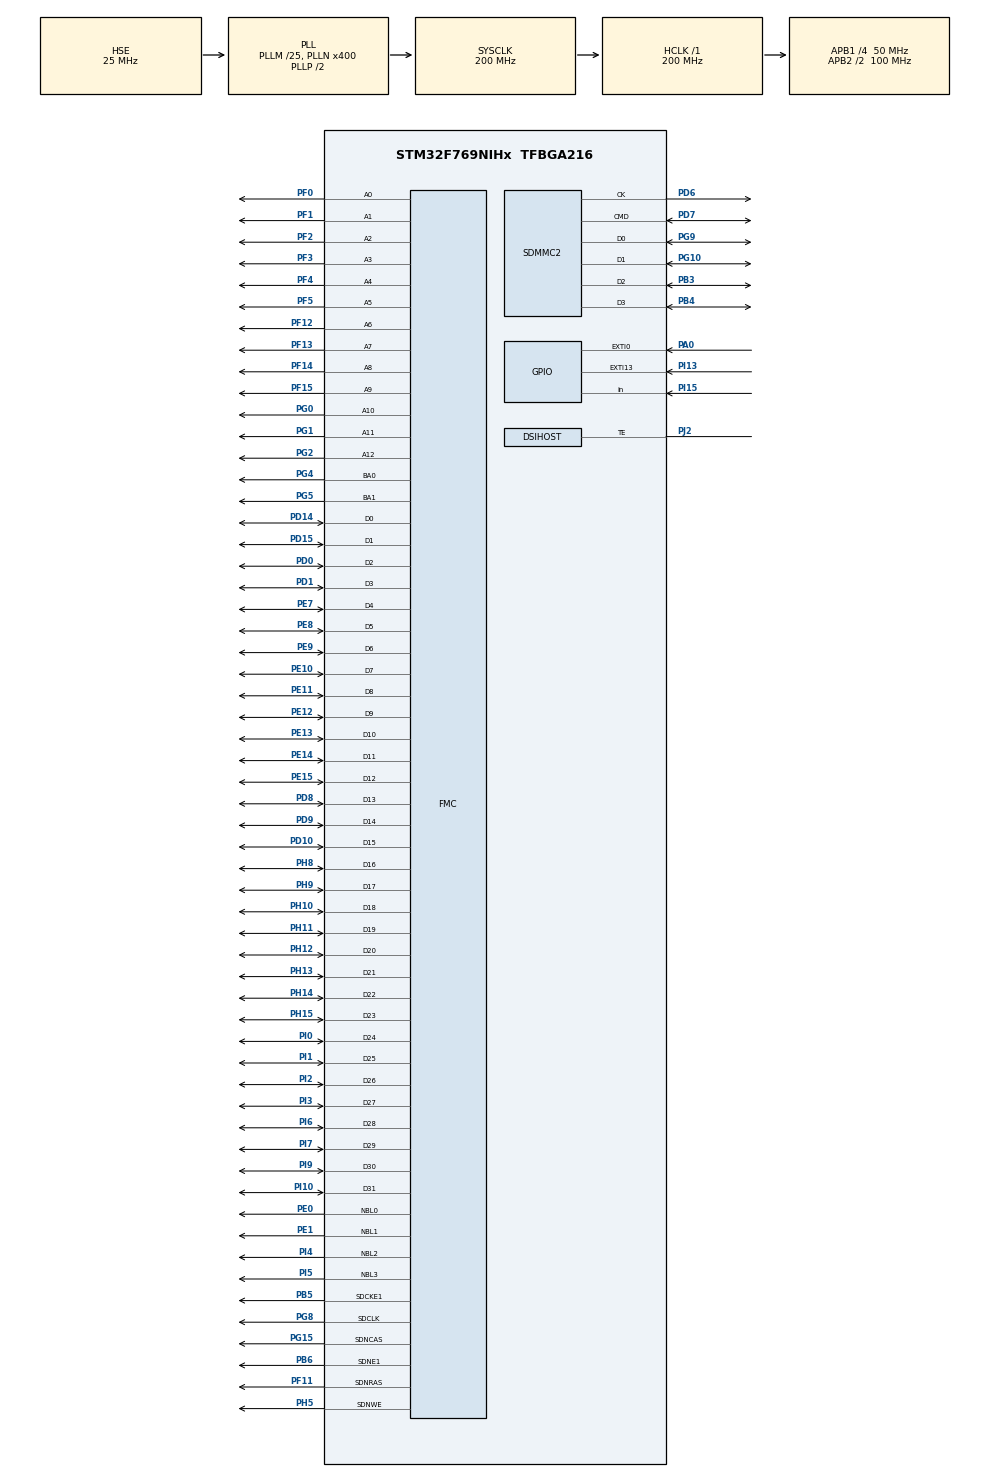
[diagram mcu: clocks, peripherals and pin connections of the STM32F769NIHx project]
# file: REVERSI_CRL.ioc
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ADC1.Channel-0\#ChannelRegularConversion=ADC_CHANNEL_TEMPSENSOR
ADC1.ContinuousConvMode=ENABLE
ADC1.EOCSelection=ADC_EOC_SEQ_CONV
ADC1.NbrOfConversionFlag=1
ADC1.Rank-0\#ChannelRegularConversion=1
ADC1.SamplingTime-0\#ChannelRegularConversion=ADC_SAMPLETIME_56CYCLES
ADC1.master=1
CORTEX_M7.CPU_DCache=Enabled
CORTEX_M7.CPU_ICache=Enabled
DSIHOST_CKN.Mode=DSIHost_Adapted_TE
DSIHOST_CKN.Signal=DSIHOST_CKN
DSIHOST_CKP.Mode=DSIHost_Adapted_TE
DSIHOST_CKP.Signal=DSIHOST_CKP
DSIHOST_D0N.Mode=DSIHost_Adapted_TE
DSIHOST_D0N.Signal=DSIHOST_D0N
DSIHOST_D0P.Mode=DSIHost_Adapted_TE
DSIHOST_D0P.Signal=DSIHOST_D0P
DSIHOST_D1N.Mode=DSIHost_Adapted_TE
DSIHOST_D1N.Signal=DSIHOST_D1N
DSIHOST_D1P.Mode=DSIHost_Adapted_TE
DSIHOST_D1P.Signal=DSIHOST_D1P
FATFS.BSP.number=1
FATFS0.BSP.STBoard=false
FATFS0.BSP.api=Unknown
FATFS0.BSP.i2caddr=0
FATFS0.BSP.instance=PI15
FATFS0.BSP.ip=GPIO
FATFS0.BSP.mode=Input
FATFS0.BSP.name=Detect_SDIO
FATFS0.BSP.solution=PI15
Mcu.Family=STM32F7
Mcu.Name=STM32F769NIHx
Mcu.Package=TFBGA216
NVIC.ADC_IRQn=true\:0\:0\:false\:false\:true\:true\:true
NVIC.EXTI0_IRQn=true\:0\:0\:false\:false\:true\:true\:true
NVIC.EXTI15_10_IRQn=true\:0\:0\:false\:false\:true\:true\:true
NVIC.PriorityGroup=NVIC_PRIORITYGROUP_4
NVIC.TIM6_DAC_IRQn=true\:0\:0\:false\:false\:true\:true\:true
NVIC.TIM7_IRQn=true\:0\:0\:false\:false\:true\:true\:true
PA0/WKUP.Signal=GPXTI0
PB3.Mode=SD_4_bits_Wide_bus
PB3.Signal=SDMMC2_D2
PB4.Mode=SD_4_bits_Wide_bus
PB4.Signal=SDMMC2_D3
PB5.Mode=SdramChipSelect2_1
PB5.Signal=FMC_SDCKE1
PB6.Mode=SdramChipSelect2_1
PB6.Signal=FMC_SDNE1
PD0.Signal=FMC_D2_DA2
PD1.Signal=FMC_D3_DA3
PD10.Signal=FMC_D15_DA15
PD14.Signal=FMC_D0_DA0
PD15.Signal=FMC_D1_DA1
PD6.Mode=SD_4_bits_Wide_bus
PD6.Signal=SDMMC2_CK
PD7.Mode=SD_4_bits_Wide_bus
PD7.Signal=SDMMC2_CMD
PD8.Signal=FMC_D13_DA13
PD9.Signal=FMC_D14_DA14
PE0.Signal=FMC_NBL0
PE1.Signal=FMC_NBL1
PE10.Signal=FMC_D7_DA7
PE11.Signal=FMC_D8_DA8
PE12.Signal=FMC_D9_DA9
PE13.Signal=FMC_D10_DA10
PE14.Signal=FMC_D11_DA11
PE15.Signal=FMC_D12_DA12
PE7.Signal=FMC_D4_DA4
PE8.Signal=FMC_D5_DA5
PE9.Signal=FMC_D6_DA6
PF0.Signal=FMC_A0
PF1.Signal=FMC_A1
PF11.Signal=FMC_SDNRAS
PF12.Signal=FMC_A6
PF13.Signal=FMC_A7
PF14.Signal=FMC_A8
PF15.Signal=FMC_A9
PF2.Signal=FMC_A2
PF3.Signal=FMC_A3
PF4.Signal=FMC_A4
PF5.Signal=FMC_A5
PG0.Signal=FMC_A10
PG1.Signal=FMC_A11
PG10.Mode=SD_4_bits_Wide_bus
PG10.Signal=SDMMC2_D1
PG15.Signal=FMC_SDNCAS
PG2.Signal=FMC_A12
PG4.Signal=FMC_A14_BA0
PG5.Signal=FMC_A15_BA1
PG8.Signal=FMC_SDCLK
PG9.Mode=SD_4_bits_Wide_bus
PG9.Signal=SDMMC2_D0
PH0/OSC_IN.Mode=HSE-External-Oscillator
PH0/OSC_IN.Signal=RCC_OSC_IN
PH1/OSC_OUT.Mode=HSE-External-Oscillator
PH1/OSC_OUT.Signal=RCC_OSC_OUT
PH10.Signal=FMC_D18
PH11.Signal=FMC_D19
PH12.Signal=FMC_D20
PH13.Signal=FMC_D21
PH14.Signal=FMC_D22
PH15.Signal=FMC_D23
PH5.Signal=FMC_SDNWE
PH8.Signal=FMC_D16
PH9.Signal=FMC_D17
PI0.Signal=FMC_D24
PI1.Signal=FMC_D25
PI10.Signal=FMC_D31
PI13.Signal=GPXTI13
PI15.Signal=GPIO_Input
PI2.Signal=FMC_D26
PI3.Signal=FMC_D27
PI4.Signal=FMC_NBL2
PI5.Signal=FMC_NBL3
PI6.Signal=FMC_D28
PI7.Signal=FMC_D29
PI9.Signal=FMC_D30
PJ2.Mode=DSIHost_Adapted_TE
PJ2.Signal=DSIHOST_TE
ProjectManager.HeapSize=0x200
ProjectManager.StackSize=0x400
ProjectManager.TargetToolchain=STM32CubeIDE
RCC.AHBFreq_Value=200000000
RCC.APB1CLKDivider=RCC_HCLK_DIV4
RCC.APB1Freq_Value=50000000
RCC.APB1TimFreq_Value=100000000
RCC.APB2CLKDivider=RCC_HCLK_DIV2
RCC.APB2Freq_Value=100000000
RCC.APB2TimFreq_Value=200000000
RCC.CortexFreq_Value=200000000
RCC.HCLKFreq_Value=200000000
RCC.HSE_VALUE=25000000
RCC.HSI_VALUE=16000000
RCC.LSE_VALUE=32768
RCC.PLLI2SN=96
RCC.PLLM=25
RCC.PLLN=400
RCC.PLLQ=8
RCC.PLLSourceVirtual=RCC_PLLSOURCE_HSE
RCC.SDMMC2ClockSelection=RCC_SDMMC2CLKSOURCE_CLK48
RCC.SYSCLKFreq_VALUE=200000000
RCC.SYSCLKSource=RCC_SYSCLKSOURCE_PLLCLK
RCC.USBFreq_Value=50000000
RCC.VCOOutputFreq_Value=400000000
SH.FMC_A0.0=FMC_A0,13b-sda1
SH.FMC_A1.0=FMC_A1,13b-sda1
SH.FMC_A10.0=FMC_A10,13b-sda1
SH.FMC_A11.0=FMC_A11,13b-sda1
SH.FMC_A12.0=FMC_A12,13b-sda1
SH.FMC_A14_BA0.0=FMC_BA0,FourSdramBanks1
SH.FMC_A15_BA1.0=FMC_BA1,FourSdramBanks1
SH.FMC_A2.0=FMC_A2,13b-sda1
SH.FMC_A3.0=FMC_A3,13b-sda1
SH.FMC_A4.0=FMC_A4,13b-sda1
SH.FMC_A5.0=FMC_A5,13b-sda1
SH.FMC_A6.0=FMC_A6,13b-sda1
SH.FMC_A7.0=FMC_A7,13b-sda1
SH.FMC_A8.0=FMC_A8,13b-sda1
SH.FMC_A9.0=FMC_A9,13b-sda1
SH.FMC_D0_DA0.0=FMC_D0,sd-32b-d1
SH.FMC_D10_DA10.0=FMC_D10,sd-32b-d1
SH.FMC_D11_DA11.0=FMC_D11,sd-32b-d1
SH.FMC_D12_DA12.0=FMC_D12,sd-32b-d1
SH.FMC_D13_DA13.0=FMC_D13,sd-32b-d1
SH.FMC_D14_DA14.0=FMC_D14,sd-32b-d1
SH.FMC_D15_DA15.0=FMC_D15,sd-32b-d1
SH.FMC_D16.0=FMC_D16,sd-32b-d1
SH.FMC_D17.0=FMC_D17,sd-32b-d1
SH.FMC_D18.0=FMC_D18,sd-32b-d1
SH.FMC_D19.0=FMC_D19,sd-32b-d1
SH.FMC_D1_DA1.0=FMC_D1,sd-32b-d1
SH.FMC_D20.0=FMC_D20,sd-32b-d1
SH.FMC_D21.0=FMC_D21,sd-32b-d1
SH.FMC_D22.0=FMC_D22,sd-32b-d1
SH.FMC_D23.0=FMC_D23,sd-32b-d1
SH.FMC_D24.0=FMC_D24,sd-32b-d1
SH.FMC_D25.0=FMC_D25,sd-32b-d1
SH.FMC_D26.0=FMC_D26,sd-32b-d1
SH.FMC_D27.0=FMC_D27,sd-32b-d1
SH.FMC_D28.0=FMC_D28,sd-32b-d1
SH.FMC_D29.0=FMC_D29,sd-32b-d1
SH.FMC_D2_DA2.0=FMC_D2,sd-32b-d1
SH.FMC_D30.0=FMC_D30,sd-32b-d1
SH.FMC_D31.0=FMC_D31,sd-32b-d1
SH.FMC_D3_DA3.0=FMC_D3,sd-32b-d1
SH.FMC_D4_DA4.0=FMC_D4,sd-32b-d1
SH.FMC_D5_DA5.0=FMC_D5,sd-32b-d1
SH.FMC_D6_DA6.0=FMC_D6,sd-32b-d1
SH.FMC_D7_DA7.0=FMC_D7,sd-32b-d1
SH.FMC_D8_DA8.0=FMC_D8,sd-32b-d1
SH.FMC_D9_DA9.0=FMC_D9,sd-32b-d1
SH.FMC_NBL0.0=FMC_NBL0,Sd4ByteEnable1
SH.FMC_NBL1.0=FMC_NBL1,Sd4ByteEnable1
SH.FMC_NBL2.0=FMC_NBL2,Sd4ByteEnable1
SH.FMC_NBL3.0=FMC_NBL3,Sd4ByteEnable1
SH.FMC_SDCLK.0=FMC_SDCLK,13b-sda1
SH.FMC_SDNCAS.0=FMC_SDNCAS,13b-sda1
SH.FMC_SDNRAS.0=FMC_SDNRAS,13b-sda1
SH.FMC_SDNWE.0=FMC_SDNWE,13b-sda1
TIM6.Period=9999
TIM6.Prescaler=9999
TIM7.Period=9999
TIM7.Prescaler=19999
VP_ADC1_TempSens_Input.Mode=IN-TempSens
VP_DMA2D_VS_DMA2D.Mode=DMA2D_Activate
VP_FATFS_VS_SDIO.Mode=SDIO
VP_LTDC_DSIMode.Mode=RGB888
VP_TIM6_VS_ClockSourceINT.Mode=Enable_Timer
VP_TIM7_VS_ClockSourceINT.Mode=Enable_Timer
board=STM32F769I-DISC1

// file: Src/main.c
/* USER CODE BEGIN Header */
/**
 ******************************************************************************
 * @file           : main.c
 * @brief          : Main program body
 ******************************************************************************
 * @attention
 *
 *
 *
 *
 *
 *
 *
 *
 ******************************************************************************
 */
/* USER CODE END Header */

#include "main.h"
#include "fatfs.h"

/* USER CODE BEGIN Includes */
#include <stdio.h>
#include <stdbool.h>
#include "stm32f769i_discovery.h"
#include "stm32f769i_discovery_ts.h"
#include "time.h"

/* USER CODE END Includes */

/* USER CODE BEGIN PTD */
typedef enum {
	MENU, SINGLEPLAYER, MULTIPLAYER, SCORES, RULES, WAIT_FOR_TOUCH
} states;

/* USER CODE END PTD */

/* USER CODE BEGIN PD */
#define TEMP_REFRESH_PERIOD   1000    /* Internal temperature refresh period */
#define MAX_CONVERTED_VALUE   4095    /* Max converted value */
#define AMBIENT_TEMP            25    /* Ambient Temperature */
#define VSENS_AT_AMBIENT_TEMP  760    /* VSENSE value (mv) at ambient temperature */
#define AVG_SLOPE               25    /* Avg_Solpe multiply by 10 */
#define VREF                  3300
#define BOARD_SIZE				 8
#define PLAYER1					 1
#define PLAYER2					 2
#define MAX_PASSED_PLAYS		 3

/* USER CODE END PD */

ADC_HandleTypeDef hadc1;

DMA2D_HandleTypeDef hdma2d;

DSI_HandleTypeDef hdsi;

LTDC_HandleTypeDef hltdc;

SD_HandleTypeDef hsd2;

TIM_HandleTypeDef htim6;
TIM_HandleTypeDef htim7;

SDRAM_HandleTypeDef hsdram1;

/* USER CODE BEGIN PV */
bool tsFlag = 0;			//Flag do touchscreen para não marcar vários toques
bool timer_1s = 0;
bool touch_timer = 1;
int touchXvalue = 0, touchYvalue = 0;//Para guardar os valores do toque de X e Y
volatile uint32_t hadc1Value = 0;				//Valor recebido na RSI
long int hadc1ConvertedValue = 0;				//Valor convertido na main
bool timer7Flag = 0;							//Flag do interrupção do Timer6
char tempString[100];						//String a ser enviada para o ecrã

int total_time = 0;
int play_timer = 20;
int num_plays = 0;
int player1_passed = 0, player2_passed = 0;

int board[BOARD_SIZE][BOARD_SIZE] = { { 0 } };

bool blue_button = 0;

TS_StateTypeDef TS_State;

/* USER CODE END PV */

void SystemClock_Config(void);
static void MX_GPIO_Init(void);
static void MX_ADC1_Init(void);
static void MX_DMA2D_Init(void);
static void MX_DSIHOST_DSI_Init(void);
static void MX_FMC_Init(void);
static void MX_LTDC_Init(void);
static void MX_SDMMC2_SD_Init(void);
static void MX_TIM6_Init(void);
static void MX_TIM7_Init(void);
/* USER CODE BEGIN PFP */
void LCD_Config_Start(void);
void LCD_Config_Rules(void);
void LCD_Gameplay(void);
void LCD_Update_Timers(void);
void show_temperature(states);
void draw_board(void);
void stamp_play(void);
void computer_stamp_play(void);
void init_board(void);
void save_2_sdcard(int player1_score, int player2_score);
bool validate_play(int cell_lin, int cell_col, int player, bool flip);
void update_board(void);
void get_scores(int *empty_cells, int *player1_score, int *player2_score);
void update_scores(int player1_score, int player2_score);
void LCD_Config_WinPanel(int player, int player_score);

/* USER CODE END PFP */

/* USER CODE BEGIN 0 */

void LCD_Update_Timers(void) {

	char string_turn[30];
	char string_time[30];

	BSP_LCD_SetTextColor(LCD_COLOR_BLACK);
	BSP_LCD_FillRect(0, 0, BSP_LCD_GetXSize(), 30);
	BSP_LCD_SetTextColor(LCD_COLOR_WHITE);
	BSP_LCD_SetBackColor(LCD_COLOR_BLACK);
	BSP_LCD_SetFont(&Font16);
	sprintf(string_time, "TOTAL ELAPSED TIME: %d", total_time);
	BSP_LCD_DisplayStringAt(0, 10, (uint8_t *) string_time, CENTER_MODE);

	BSP_LCD_SetTextColor(LCD_COLOR_BLACK);
	BSP_LCD_FillRect(0, 460, BSP_LCD_GetXSize(), 30);
	BSP_LCD_SetTextColor(LCD_COLOR_WHITE);
	BSP_LCD_SetBackColor(LCD_COLOR_BLACK);
	BSP_LCD_SetFont(&Font16);
	sprintf(string_turn, "YOUR TURN ENDS IN: %d", play_timer);
	BSP_LCD_DisplayStringAt(0, 460, (uint8_t *) string_turn, CENTER_MODE);
}

void save_2_sdcard(int player1_score, int player2_score) {

	unsigned int nBytes = 0;
	char string1[20], string2[20];

	if (f_mount(&SDFatFS, SDPath, 0) != FR_OK)
		Error_Handler();

	if (f_open(&SDFile, "reversi.txt", FA_WRITE | FA_CREATE_ALWAYS) != FR_OK)
		Error_Handler();

	sprintf(string1, "PLAYER1 - %d", player1_score);
	sprintf(string2, "PLAYER2 - %d", player2_score);

	if (f_write(&SDFile, string1, strlen(string1), &nBytes) != FR_OK)
		Error_Handler();
	if (f_write(&SDFile, string2, strlen(string2), &nBytes) != FR_OK)
		Error_Handler();

	f_close(&SDFile);
}

void init_board(void) {

	for (int i = 0; i < BOARD_SIZE; i++) {
		for (int j = 0; j < BOARD_SIZE; j++) {
			board[i][j] = (int) '.';
		}
	}

	board[BOARD_SIZE / 2 - 1][BOARD_SIZE / 2 - 1] = PLAYER1;
	board[BOARD_SIZE / 2][BOARD_SIZE / 2] = PLAYER1;
	board[BOARD_SIZE / 2 - 1][BOARD_SIZE / 2] = PLAYER2;
	board[BOARD_SIZE / 2][BOARD_SIZE / 2 - 1] = PLAYER2;
}

void show_temperature(states state) {

	/* Mostra a temperatura, mas apenas a atualiza de 2 em 2 segundos */

	if (timer7Flag == 1) {

		timer7Flag = 0;

		hadc1ConvertedValue = ((((hadc1Value * VREF) / MAX_CONVERTED_VALUE)
				- VSENS_AT_AMBIENT_TEMP) * 10 / AVG_SLOPE) + AMBIENT_TEMP;
	}
	if (state == SINGLEPLAYER || state == MULTIPLAYER || state == RULES || state == WAIT_FOR_TOUCH) {
		BSP_LCD_SetTextColor(LCD_COLOR_WHITE);
		BSP_LCD_SetBackColor(LCD_COLOR_BLACK);
	} else {
		BSP_LCD_SetTextColor(LCD_COLOR_BLACK);
		BSP_LCD_SetBackColor(LCD_COLOR_WHITE);
	}

	sprintf(tempString, "Temp: %ldC", hadc1ConvertedValue);
	BSP_LCD_DisplayStringAt(0, BSP_LCD_GetYSize() - 20, (uint8_t *) tempString,
			RIGHT_MODE);

}

void draw_board(void) {

	BSP_LCD_SetTextColor(LCD_COLOR_BLACK);

	for (int i = 1; i <= 9; i++) {
		BSP_LCD_DrawVLine(150 + (i * 50), 40, 400);
		BSP_LCD_DrawHLine(200, (i * 50) - 10, 400);
	}
}

bool validate_play(int cell_lin, int cell_col, int player, bool flip) {

	int i = 0, j = 0;
	bool valid = 0, valid_play = 0;

	if (board[cell_lin][cell_col] != '.') {
		return 0;
	}

	//Check left diagonal inferior
	for (i = cell_lin - 1, j = cell_col - 1; i >= 0 && j >= 0; i--, j--) {
		if (!valid) {
			if (board[i][j] == '.')
				break;
			else if (board[i][j] == player)
				break;
			else
				valid = 1;
		} else if (board[i][j] == player) {
			if (flip)
				for (int k = cell_lin - 1, x = cell_col - 1; k > i && x > j;
						k--, x--)
					board[k][x] = player;
			valid_play = 1;
		}
	}

	//Vertical Inferior
	valid = 0;
	for (i = cell_lin - 1, j = cell_col; i >= 0; i--) {
		if (!valid) {
			if (board[i][j] == '.')
				break;
			else if (board[i][j] == player)
				break;
			else
				valid = 1;
		} else if (board[i][j] == player) {
			if (flip)
				for (int k = cell_lin - 1; k > i; k--)
					board[k][j] = player;
			valid_play = 1;
		}
	}

	//Inferior Right Diagonal
	valid = 0;
	for (i = cell_lin - 1, j = cell_col + 1; i > 0 && j < BOARD_SIZE;
			i--, j++) {
		if (!valid) {
			if (board[i][j] == '.')
				break;
			else if (board[i][j] == player)
				break;
			else
				valid = 1;
		} else if (board[i][j] == player) {
			if (flip)
				for (int k = cell_lin - 1, x = cell_col + 1; k > i && x < j;
						k--, x++)
					board[k][x] = player;
			valid_play = 1;
		}
	}

	//Right Horizontal
	valid = 0;
	for (i = cell_lin, j = cell_col + 1; j < BOARD_SIZE; j++) {
		if (!valid) {
			if (board[i][j] == '.')
				break;
			else if (board[i][j] == player)
				break;
			else
				valid = 1;
		} else if (board[i][j] == player) {
			if (flip)
				for (int x = cell_col + 1; x < j; x++)
					board[i][x] = player;
			valid_play = 1;
		}
	}

	//Right Diagonal Superior
	valid = 0;
	for (i = cell_lin + 1, j = cell_col + 1; i < BOARD_SIZE && j < BOARD_SIZE;
			i++, j++) {
		if (!valid) {
			if (board[i][j] == '.')
				break;
			else if (board[i][j] == player)
				break;
			else
				valid = 1;
		} else if (board[i][j] == player) {
			if (flip)
				for (int k = cell_lin + 1, x = cell_col + 1; k < i && x < j;
						k++, x++)
					board[k][x] = player;
			valid_play = 1;
		}
	}

	//Vertical Superior
	valid = 0;
	for (i = cell_lin + 1, j = cell_col; i < BOARD_SIZE; i++) {
		if (!valid) {
			if (board[i][j] == '.')
				break;
			else if (board[i][j] == player)
				break;
			else
				valid = 1;
		} else if (board[i][j] == player) {
			if (flip)
				for (int k = cell_lin + 1; k < i; k++)
					board[k][j] = player;
			valid_play = 1;
		}
	}

	//Superior Left Diagonal
	valid = 0;
	for (i = cell_lin + 1, j = cell_col - 1; i < BOARD_SIZE && j >= 0;
			i++, j--) {
		if (!valid) {
			if (board[i][j] == '.')
				break;
			else if (board[i][j] == player)
				break;
			else
				valid = 1;
		} else if (board[i][j] == player) {
			if (flip)
				for (int k = cell_lin + 1, x = cell_col - 1; k < i && x > j;
						k++, x--)
					board[k][x] = player;
			valid_play = 1;
		}
	}

	//Left Horizontal
	valid = 0;
	for (i = cell_lin, j = cell_col - 1; j >= 0; j--) {
		if (!valid) {
			if (board[i][j] == '.')
				break;
			else if (board[i][j] == player)
				break;
			else
				valid = 1;
		} else if (board[i][j] == player) {
			if (flip)
				for (int x = cell_col - 1; x > j; x--)
					board[i][x] = player;
			valid_play = 1;
		}
	}
	return valid_play;
}

void stamp_play(void) {

	int player, N_possible_plays = 0;

	int cell_lin, cell_col;

	/* Check player's turn */
	if (num_plays % 2 == 0) {
		BSP_LED_On(LED_RED);
		player = PLAYER1;
	}

	else {
		BSP_LED_On(LED_GREEN);
		player = PLAYER2;
	}

	/* Check the number of possible plays */
	for (int i = 0; i < BOARD_SIZE; i++) {
		for (int j = 0; j < BOARD_SIZE; j++) {
			if (validate_play(i, j, player, 0)) {
				N_possible_plays++;
			}
		}
	}

	if (N_possible_plays == 0)
		play_timer = 0;

	/* If there's play time left */
	if (play_timer > 0) {

		if (tsFlag == 1) {

			tsFlag = 0;

			/* If the desired play is inside the board game*/
			if (TS_State.touchX[0] > 200 && TS_State.touchX[0] < 600
					&& TS_State.touchY[0] > 40 && TS_State.touchY[0] < 440) {

				cell_lin = (TS_State.touchX[0] - 200) / 50;
				cell_col = (TS_State.touchY[0] - 40) / 50;

				/* Check if the play is valid */
				if (validate_play(cell_lin, cell_col, player, 1)) {
					board[cell_lin][cell_col] = player;

					update_board();

					TS_State.touchX[0] = 0;
					TS_State.touchY[0] = 0;
					BSP_LED_Off(LED_RED);
					BSP_LED_Off(LED_GREEN);

					num_plays++;
					play_timer = 20;

					/* Check for player turn and reset his number of passed plays */
					if (num_plays % 2 == 0)
						player1_passed = 0;
					else
						player2_passed = 0;
					return;

				} else
					return;
			}
		}

	/*If the play time has reached the limit */
	} else if (play_timer == 0){			//Flag do Extra GOAL

		BSP_LED_Off(LED_GREEN);
		BSP_LED_Off(LED_RED);
		num_plays++;

		if (num_plays % 2 == 0)
			player1_passed++;
		else
			player2_passed++;

		play_timer = 20;
		return;
	}
}

void singleplayer_stamp_play(void) {

	int player, N_possible_plays = 0;

	int cell_lin, cell_col;

	/* Check for player's turn */
	if (num_plays % 2 == 0) {
		BSP_LED_On(LED_RED);
		player = PLAYER1;
	}

	else {
		BSP_LED_On(LED_GREEN);
		player = PLAYER2;
	}

	/* If it's Player2 turn (computer) leave this function */
	if(player == PLAYER2)
			return;

	for (int i = 0; i < BOARD_SIZE; i++) {
		for (int j = 0; j < BOARD_SIZE; j++) {
			if (validate_play(i, j, player, 0)) {
				N_possible_plays++;
			}
		}
	}

	if (N_possible_plays == 0)
		play_timer = 0;

	/* If there's time left to play */
	if (play_timer > 0) {

		if (tsFlag == 1) {

			tsFlag = 0;

			/* If there touch was inside the board, convert it */
			if (TS_State.touchX[0] > 200 && TS_State.touchX[0] < 600
					&& TS_State.touchY[0] > 40 && TS_State.touchY[0] < 440) {

				cell_lin = (TS_State.touchX[0] - 200) / 50;
				cell_col = (TS_State.touchY[0] - 40) / 50;

				/* Check if the play is valid */
				if (validate_play(cell_lin, cell_col, player, 1)) {
					board[cell_lin][cell_col] = player;

					update_board();

					/* Reset the variables */
					TS_State.touchX[0] = 0;
					TS_State.touchY[0] = 0;
					BSP_LED_Off(LED_RED);
					BSP_LED_Off(LED_GREEN);

					num_plays++;
					play_timer = 20;

					/* Check for the player turn and reset the number of plays */
					if (num_plays % 2 == 0)
						player1_passed = 0;
					else
						player2_passed = 0;
					return;
				} else
					return;
			}
		}

	/* If there's no time left to play */
	} else {

		BSP_LED_Off(LED_GREEN);
		BSP_LED_Off(LED_RED);
		num_plays++;

		/* Check player's turn */
		if (num_plays % 2 == 0)
			player1_passed++;
		else
			player2_passed++;

		play_timer = 20;
		return;
	}
}

void update_board(void) {

	/* Update the LCD board in with the new values in the matrix board */

	BSP_LCD_Clear(LCD_COLOR_WHITE);
	LCD_Update_Timers();
	LCD_Gameplay();

	for (int i = 0; i < BOARD_SIZE; i++) {
		for (int j = 0; j < BOARD_SIZE; j++) {
			int posX = 200 + (i) * 50;
			int posY = 40 + (j) * 50;

			if (board[i][j] == PLAYER1) {
				BSP_LCD_SetTextColor(LCD_COLOR_RED);
				BSP_LCD_FillCircle(posX + 25, posY + 25, 20);

			} else if (board[i][j] == PLAYER2) {
				BSP_LCD_SetTextColor(LCD_COLOR_GREEN);
				BSP_LCD_FillCircle(posX + 25, posY + 25, 20);
			}
		}
	}
}

void update_scores(int player1_score, int player2_score) {

	char p1_score[3], p2_score[3];

	/* SCORE PLAYER 1*/
	BSP_LCD_SetTextColor(LCD_COLOR_BLACK);
	BSP_LCD_SetBackColor(LCD_COLOR_WHITE);
	BSP_LCD_SetFont(&Font24);
	sprintf(p1_score," %d", player1_score);
	BSP_LCD_DisplayStringAt(30, 140, (uint8_t *) p1_score, LEFT_MODE);

	/* SCORE PLAYER 2*/
	BSP_LCD_SetTextColor(LCD_COLOR_BLACK);
	BSP_LCD_SetBackColor(LCD_COLOR_WHITE);
	BSP_LCD_SetFont(&Font24);
	sprintf(p2_score, " %d", player2_score);
	BSP_LCD_DisplayStringAt(630, 140, (uint8_t *) p2_score, LEFT_MODE);
}

void get_scores(int *empty_cells, int *player1_score, int *player2_score) {		//Goal EXTRA

	*empty_cells = 0;
	*player1_score = 0;
	*player2_score = 0;

	if (player1_passed == MAX_PASSED_PLAYS) {
		*player1_score = 0;
		*player2_score = 65;
		return;
	}
	if (player2_passed == MAX_PASSED_PLAYS) {
		*player1_score = 65;
		*player2_score = 0;
		return;
	}

	for (int i = 0; i < BOARD_SIZE; i++) {
		for (int j = 0; j < BOARD_SIZE; j++) {

			if (board[i][j] == '.')
				(*empty_cells)++;
			else if (board[i][j] == PLAYER1)
				(*player1_score)++;
			else if (board[i][j] == PLAYER2)
				(*player2_score)++;
		}
	}
}

void LCD_Config_WinPanel(int player, int player_score) {

	char score_string[3];
	char player_string[20];

	BSP_LCD_Clear(LCD_COLOR_WHITE);

	BSP_LCD_SetTextColor(LCD_COLOR_BLACK);
	BSP_LCD_FillRect(0, 0, BSP_LCD_GetXSize(), BSP_LCD_GetYSize());

	BSP_LCD_SetTextColor(LCD_COLOR_WHITE);
	BSP_LCD_SetBackColor(LCD_COLOR_BLACK);
	BSP_LCD_SetFont(&Font24);
	BSP_LCD_DisplayStringAt(0, 240, (uint8_t *) "WINNER!", CENTER_MODE);

	BSP_LCD_SetFont(&Font16);

	if (player_score == 65) {
		BSP_LCD_DisplayStringAt(0, 320, (uint8_t *) "K.O.", CENTER_MODE);
	}
	else {

		if (player == PLAYER1)
			BSP_LCD_SetTextColor(LCD_COLOR_RED);
		else
			BSP_LCD_SetTextColor(LCD_COLOR_GREEN);
	}

	sprintf(player_string, "PLAYER%d", player);
	BSP_LCD_DisplayStringAt(0, 270, (uint8_t *) player_string, CENTER_MODE);
	sprintf(score_string, " %d", player_score);
	BSP_LCD_DisplayStringAt(0, 300, (uint8_t *) score_string, CENTER_MODE);
}

void computer_stamp_play(void) {

	int player, N_possible_plays = 0, possible_play = 0;

	/* Check player's turn to turn on his LED Color */
	if (num_plays % 2 == 0) {
		BSP_LED_On(LED_RED);
		player = PLAYER1;
	}

	else {
		BSP_LED_On(LED_GREEN);
		player = PLAYER2;
	}

	/* If it's player 1 turn end this function */
	if(player == PLAYER1)
		return;

	/* Coun the number of possible plays */
	if (play_timer > 0) {
		for (int i = 0; i < BOARD_SIZE; i++) {
			for (int j = 0; j < BOARD_SIZE; j++) {
				if (validate_play(i, j, player, 0)) {
					N_possible_plays++;
				}
			}
		}

		/* If there are no plays left */
		if(N_possible_plays == 0){
			BSP_LED_Off(LED_GREEN);
			BSP_LED_On(LED_RED);
			num_plays++;
			player2_passed++;
			play_timer = 20;
			return;
		}

		/* Gets a random value of the play */
		srand(time(NULL));
		int random_play = rand() % N_possible_plays + 1;

		/* Gets the number of possible plays and if it match the pretended play
		 * save it into the matrix + validate the play. */
		for (int i = 0; i < BOARD_SIZE; i++) {
			for (int j = 0; j < BOARD_SIZE; j++) {
				if (validate_play(i, j, player, 0)) {
					possible_play++;
					if (possible_play == random_play) {
						validate_play(i, j, player, 1);
						board[i][j] = player;
						update_board();
						num_plays++;
						play_timer = 20;
						player2_passed = 0;
						BSP_LED_Off(LED_GREEN);
						BSP_LED_Off(LED_RED);
						return;
					}
				}
			}
		}
	}

	/* If the time's up */
	else {

		BSP_LED_Off(LED_GREEN);
		BSP_LED_Off(LED_RED);
		num_plays++;
		if (num_plays % 2 == 0)
			player1_passed++;
		else
			player2_passed++;

		play_timer = 20;
		return;
	}
}
/* USER CODE END 0 */

int main(void) {
	/* USER CODE BEGIN 1 */
	//states state = MENU;
	/* USER CODE END 1 */

	/* Enable I-Cache---------------------------------------------------------*/
	SCB_EnableICache();

	/* Enable D-Cache---------------------------------------------------------*/
	SCB_EnableDCache();

	/* MCU Configuration--------------------------------------------------------*/

	/* Reset of all peripherals, Initializes the Flash interface and the Systick. */
	HAL_Init();

	/* Configure the system clock */
	SystemClock_Config();

	/* Initialize all configured peripherals */
	MX_GPIO_Init();
	MX_ADC1_Init();
	MX_DMA2D_Init();
	MX_DSIHOST_DSI_Init();
	MX_FMC_Init();
	MX_LTDC_Init();
	MX_SDMMC2_SD_Init();
	MX_TIM6_Init();
	MX_TIM7_Init();
	MX_FATFS_Init();
	/* USER CODE BEGIN 2 */
	BSP_LED_Init(LED_RED);
	BSP_LED_Init(LED_GREEN);
	HAL_TIM_Base_Start_IT(&htim6);
	HAL_TIM_Base_Start_IT(&htim7);
	HAL_ADC_Start_IT(&hadc1);
	BSP_TS_Init(BSP_LCD_GetXSize(), BSP_LCD_GetYSize());
	BSP_TS_ITConfig();
	LCD_Config_Start();
	init_board();

	states state = MENU;
	char screen_refresh;

	int empty_cells, player1_score, player2_score;

	/* USER CODE END 2 */

	/* Infinite loop */
	/* USER CODE BEGIN WHILE */
	while (1) {

		show_temperature(state);

		switch (state) {

		case SINGLEPLAYER:
			//SINGLE PLAYER MODE
			if (screen_refresh) {	//Flag for New Game
				while (!timer_1s);	//Holds till it passes 1 sec
				timer_1s = 0;

				BSP_LCD_Clear(LCD_COLOR_WHITE);

				init_board();

				play_timer = 20;
				total_time = 0;
				LCD_Update_Timers();

				LCD_Gameplay();
				update_board();

				screen_refresh = 0;
			}
			if (timer_1s) {		//Flag for showing timer
				LCD_Update_Timers();
				timer_1s = 0;
			}
			singleplayer_stamp_play();
			computer_stamp_play();

			get_scores(&empty_cells, &player1_score, &player2_score);

			update_scores(player1_score, player2_score);

			if ((empty_cells == 0) || (player1_score == 0)
					|| (player2_score == 0)) {					//Fim de casa livres || jogadas disponíveis

				save_2_sdcard(player1_score, player2_score);

				if (player1_score > player2_score)
					LCD_Config_WinPanel(PLAYER1, player1_score);
				else
					LCD_Config_WinPanel(PLAYER2, player2_score);

				state = WAIT_FOR_TOUCH;
			}

			break;

		case MULTIPLAYER:
			//MULTIPLAYER MODE
			if (screen_refresh) {		//New Game Flag
				while (!timer_1s);		//Holds till it pass 1 sec
				timer_1s = 0;

				BSP_LCD_Clear(LCD_COLOR_WHITE);

				init_board();

				play_timer = 20;
				total_time = 0;
				LCD_Update_Timers();

				LCD_Gameplay();
				update_board();

				screen_refresh = 0;
			}

			if (timer_1s) {			//Flag for showing timer
				LCD_Update_Timers();
				timer_1s = 0;
			}

			stamp_play();

			get_scores(&empty_cells, &player1_score, &player2_score);

			update_scores(player1_score, player2_score);
			if ((empty_cells == 0) || (player1_score == 0)
					|| (player2_score == 0)) {

				save_2_sdcard(player1_score, player2_score);

				if (player1_score > player2_score)
					LCD_Config_WinPanel(PLAYER1, player1_score);
				else
					LCD_Config_WinPanel(PLAYER2, player2_score);

				state = WAIT_FOR_TOUCH;
			}

			break;

		case SCORES:
			//SCORES
			break;

		case RULES:
			//RULES
			BSP_LCD_Clear(LCD_COLOR_WHITE);
			LCD_Config_Rules();
			screen_refresh = 0;

			state = WAIT_FOR_TOUCH;
			break;

		case WAIT_FOR_TOUCH:
			if (tsFlag == 1) {
				tsFlag = 0;
				LCD_Config_Start();
				state = MENU;
			}
			break;

		case MENU:

			if (tsFlag == 1 && touchXvalue != 0 && touchYvalue != 0) {

				tsFlag = 0;

				if (touchXvalue <= 200) {
					screen_refresh = 1;
					state = SINGLEPLAYER;
				}

				else if (touchXvalue > 200 && touchXvalue <= 400) {
					screen_refresh = 1;
					state = MULTIPLAYER;
				}

				else if (touchXvalue > 400 && touchXvalue <= 600) {
					screen_refresh = 1;
					state = SCORES;
				}

				else if (touchXvalue > 600 && touchXvalue <= 800) {
					state = RULES;
				}
			}
			break;
		}

		if (blue_button) {
			state = MENU;
			LCD_Config_Start();
			num_plays = 0;
			blue_button = 0;
		}

		/* USER CODE END WHILE */

	}
}

void SystemClock_Config(void) {
	RCC_OscInitTypeDef RCC_OscInitStruct = { 0 };
	RCC_ClkInitTypeDef RCC_ClkInitStruct = { 0 };
	RCC_PeriphCLKInitTypeDef PeriphClkInitStruct = { 0 };

	/** Configure the main internal regulator output voltage
	 */
	__HAL_RCC_PWR_CLK_ENABLE()
	;
	__HAL_PWR_VOLTAGESCALING_CONFIG(PWR_REGULATOR_VOLTAGE_SCALE1);
	/** Initializes the CPU, AHB and APB busses clocks
	 */
	RCC_OscInitStruct.OscillatorType = RCC_OSCILLATORTYPE_HSE;
	RCC_OscInitStruct.HSEState = RCC_HSE_ON;
	RCC_OscInitStruct.PLL.PLLState = RCC_PLL_ON;
	RCC_OscInitStruct.PLL.PLLSource = RCC_PLLSOURCE_HSE;
	RCC_OscInitStruct.PLL.PLLM = 25;
	RCC_OscInitStruct.PLL.PLLN = 400;
	RCC_OscInitStruct.PLL.PLLP = RCC_PLLP_DIV2;
	RCC_OscInitStruct.PLL.PLLQ = 8;
	if (HAL_RCC_OscConfig(&RCC_OscInitStruct) != HAL_OK) {
		Error_Handler();
	}
	/** Activate the Over-Drive mode
	 */
	if (HAL_PWREx_EnableOverDrive() != HAL_OK) {
		Error_Handler();
	}
	/** Initializes the CPU, AHB and APB busses clocks
	 */
	RCC_ClkInitStruct.ClockType = RCC_CLOCKTYPE_HCLK | RCC_CLOCKTYPE_SYSCLK
			| RCC_CLOCKTYPE_PCLK1 | RCC_CLOCKTYPE_PCLK2;
	RCC_ClkInitStruct.SYSCLKSource = RCC_SYSCLKSOURCE_PLLCLK;
	RCC_ClkInitStruct.AHBCLKDivider = RCC_SYSCLK_DIV1;
	RCC_ClkInitStruct.APB1CLKDivider = RCC_HCLK_DIV4;
	RCC_ClkInitStruct.APB2CLKDivider = RCC_HCLK_DIV2;

	if (HAL_RCC_ClockConfig(&RCC_ClkInitStruct, FLASH_LATENCY_6) != HAL_OK) {
		Error_Handler();
	}
	PeriphClkInitStruct.PeriphClockSelection = RCC_PERIPHCLK_LTDC
			| RCC_PERIPHCLK_SDMMC2 | RCC_PERIPHCLK_CLK48;
	PeriphClkInitStruct.PLLSAI.PLLSAIN = 192;
	PeriphClkInitStruct.PLLSAI.PLLSAIR = 2;
	PeriphClkInitStruct.PLLSAI.PLLSAIQ = 2;
	PeriphClkInitStruct.PLLSAI.PLLSAIP = RCC_PLLSAIP_DIV2;
	PeriphClkInitStruct.PLLSAIDivQ = 1;
	PeriphClkInitStruct.PLLSAIDivR = RCC_PLLSAIDIVR_2;
	PeriphClkInitStruct.Clk48ClockSelection = RCC_CLK48SOURCE_PLL;
	PeriphClkInitStruct.Sdmmc2ClockSelection = RCC_SDMMC2CLKSOURCE_CLK48;
	if (HAL_RCCEx_PeriphCLKConfig(&PeriphClkInitStruct) != HAL_OK) {
		Error_Handler();
	}
}

static void MX_ADC1_Init(void) {

	ADC_ChannelConfTypeDef sConfig = { 0 };

	/** Configure the global features of the ADC (Clock, Resolution, Data Alignment and number of conversion)
	 */
	hadc1.Instance = ADC1;
	hadc1.Init.ClockPrescaler = ADC_CLOCK_SYNC_PCLK_DIV4;
	hadc1.Init.Resolution = ADC_RESOLUTION_12B;
	hadc1.Init.ScanConvMode = DISABLE;
	hadc1.Init.ContinuousConvMode = ENABLE;
	hadc1.Init.DiscontinuousConvMode = DISABLE;
	hadc1.Init.ExternalTrigConvEdge = ADC_EXTERNALTRIGCONVEDGE_NONE;
	hadc1.Init.ExternalTrigConv = ADC_SOFTWARE_START;
	hadc1.Init.DataAlign = ADC_DATAALIGN_RIGHT;
	hadc1.Init.NbrOfConversion = 1;
	hadc1.Init.DMAContinuousRequests = DISABLE;
	hadc1.Init.EOCSelection = ADC_EOC_SEQ_CONV;
	if (HAL_ADC_Init(&hadc1) != HAL_OK) {
		Error_Handler();
	}
	/** Configure for the selected ADC regular channel its corresponding rank in the sequencer and its sample time.
	 */
	sConfig.Channel = ADC_CHANNEL_TEMPSENSOR;
	sConfig.Rank = ADC_REGULAR_RANK_1;
	sConfig.SamplingTime = ADC_SAMPLETIME_56CYCLES;
	if (HAL_ADC_ConfigChannel(&hadc1, &sConfig) != HAL_OK) {
		Error_Handler();
	}

}

static void MX_DMA2D_Init(void) {

	hdma2d.Instance = DMA2D;
	hdma2d.Init.Mode = DMA2D_M2M;
	hdma2d.Init.ColorMode = DMA2D_OUTPUT_ARGB8888;
	hdma2d.Init.OutputOffset = 0;
	hdma2d.LayerCfg[1].InputOffset = 0;
	hdma2d.LayerCfg[1].InputColorMode = DMA2D_INPUT_ARGB8888;
	hdma2d.LayerCfg[1].AlphaMode = DMA2D_NO_MODIF_ALPHA;
	hdma2d.LayerCfg[1].InputAlpha = 0;
	hdma2d.LayerCfg[1].AlphaInverted = DMA2D_REGULAR_ALPHA;
	hdma2d.LayerCfg[1].RedBlueSwap = DMA2D_RB_REGULAR;
	if (HAL_DMA2D_Init(&hdma2d) != HAL_OK) {
		Error_Handler();
	}
	if (HAL_DMA2D_ConfigLayer(&hdma2d, 1) != HAL_OK) {
		Error_Handler();
	}

}

static void MX_DSIHOST_DSI_Init(void) {

	DSI_PLLInitTypeDef PLLInit = { 0 };
	DSI_HOST_TimeoutTypeDef HostTimeouts = { 0 };
	DSI_PHY_TimerTypeDef PhyTimings = { 0 };
	DSI_LPCmdTypeDef LPCmd = { 0 };
	DSI_CmdCfgTypeDef CmdCfg = { 0 };

	hdsi.Instance = DSI;
	hdsi.Init.AutomaticClockLaneControl = DSI_AUTO_CLK_LANE_CTRL_DISABLE;
	hdsi.Init.TXEscapeCkdiv = 4;
	hdsi.Init.NumberOfLanes = DSI_ONE_DATA_LANE;
	PLLInit.PLLNDIV = 20;
	PLLInit.PLLIDF = DSI_PLL_IN_DIV1;
	PLLInit.PLLODF = DSI_PLL_OUT_DIV1;
	if (HAL_DSI_Init(&hdsi, &PLLInit) != HAL_OK) {
		Error_Handler();
	}
	HostTimeouts.TimeoutCkdiv = 1;
	HostTimeouts.HighSpeedTransmissionTimeout = 0;
	HostTimeouts.LowPowerReceptionTimeout = 0;
	HostTimeouts.HighSpeedReadTimeout = 0;
	HostTimeouts.LowPowerReadTimeout = 0;
	HostTimeouts.HighSpeedWriteTimeout = 0;
	HostTimeouts.HighSpeedWritePrespMode = DSI_HS_PM_DISABLE;
	HostTimeouts.LowPowerWriteTimeout = 0;
	HostTimeouts.BTATimeout = 0;
	if (HAL_DSI_ConfigHostTimeouts(&hdsi, &HostTimeouts) != HAL_OK) {
		Error_Handler();
	}
	PhyTimings.ClockLaneHS2LPTime = 28;
	PhyTimings.ClockLaneLP2HSTime = 33;
	PhyTimings.DataLaneHS2LPTime = 15;
	PhyTimings.DataLaneLP2HSTime = 25;
	PhyTimings.DataLaneMaxReadTime = 0;
	PhyTimings.StopWaitTime = 0;
	if (HAL_DSI_ConfigPhyTimer(&hdsi, &PhyTimings) != HAL_OK) {
		Error_Handler();
	}
	if (HAL_DSI_ConfigFlowControl(&hdsi, DSI_FLOW_CONTROL_BTA) != HAL_OK) {
		Error_Handler();
	}
	if (HAL_DSI_SetLowPowerRXFilter(&hdsi, 10000) != HAL_OK) {
		Error_Handler();
	}
	if (HAL_DSI_ConfigErrorMonitor(&hdsi, HAL_DSI_ERROR_NONE) != HAL_OK) {
		Error_Handler();
	}
	LPCmd.LPGenShortWriteNoP = DSI_LP_GSW0P_DISABLE;
	LPCmd.LPGenShortWriteOneP = DSI_LP_GSW1P_DISABLE;
	LPCmd.LPGenShortWriteTwoP = DSI_LP_GSW2P_DISABLE;
	LPCmd.LPGenShortReadNoP = DSI_LP_GSR0P_DISABLE;
	LPCmd.LPGenShortReadOneP = DSI_LP_GSR1P_DISABLE;
	LPCmd.LPGenShortReadTwoP = DSI_LP_GSR2P_DISABLE;
	LPCmd.LPGenLongWrite = DSI_LP_GLW_DISABLE;
	LPCmd.LPDcsShortWriteNoP = DSI_LP_DSW0P_DISABLE;
	LPCmd.LPDcsShortWriteOneP = DSI_LP_DSW1P_DISABLE;
	LPCmd.LPDcsShortReadNoP = DSI_LP_DSR0P_DISABLE;
	LPCmd.LPDcsLongWrite = DSI_LP_DLW_DISABLE;
	LPCmd.LPMaxReadPacket = DSI_LP_MRDP_DISABLE;
	LPCmd.AcknowledgeRequest = DSI_ACKNOWLEDGE_DISABLE;
	if (HAL_DSI_ConfigCommand(&hdsi, &LPCmd) != HAL_OK) {
		Error_Handler();
	}
	CmdCfg.VirtualChannelID = 0;
	CmdCfg.ColorCoding = DSI_RGB888;
	CmdCfg.CommandSize = 640;
	CmdCfg.TearingEffectSource = DSI_TE_EXTERNAL;
	CmdCfg.TearingEffectPolarity = DSI_TE_RISING_EDGE;
	CmdCfg.HSPolarity = DSI_HSYNC_ACTIVE_LOW;
	CmdCfg.VSPolarity = DSI_VSYNC_ACTIVE_LOW;
	CmdCfg.DEPolarity = DSI_DATA_ENABLE_ACTIVE_HIGH;
	CmdCfg.VSyncPol = DSI_VSYNC_FALLING;
	CmdCfg.AutomaticRefresh = DSI_AR_ENABLE;
	CmdCfg.TEAcknowledgeRequest = DSI_TE_ACKNOWLEDGE_DISABLE;
	if (HAL_DSI_ConfigAdaptedCommandMode(&hdsi, &CmdCfg) != HAL_OK) {
		Error_Handler();
	}
	if (HAL_DSI_SetGenericVCID(&hdsi, 0) != HAL_OK) {
		Error_Handler();
	}

}

static void MX_LTDC_Init(void) {

	LTDC_LayerCfgTypeDef pLayerCfg = { 0 };
	LTDC_LayerCfgTypeDef pLayerCfg1 = { 0 };

	hltdc.Instance = LTDC;
	hltdc.Init.HSPolarity = LTDC_HSPOLARITY_AL;
	hltdc.Init.VSPolarity = LTDC_VSPOLARITY_AL;
	hltdc.Init.DEPolarity = LTDC_DEPOLARITY_AL;
	hltdc.Init.PCPolarity = LTDC_PCPOLARITY_IPC;
	hltdc.Init.HorizontalSync = 7;
	hltdc.Init.VerticalSync = 3;
	hltdc.Init.AccumulatedHBP = 14;
	hltdc.Init.AccumulatedVBP = 5;
	hltdc.Init.AccumulatedActiveW = 654;
	hltdc.Init.AccumulatedActiveH = 485;
	hltdc.Init.TotalWidth = 660;
	hltdc.Init.TotalHeigh = 487;
	hltdc.Init.Backcolor.Blue = 0;
	hltdc.Init.Backcolor.Green = 0;
	hltdc.Init.Backcolor.Red = 0;
	if (HAL_LTDC_Init(&hltdc) != HAL_OK) {
		Error_Handler();
	}
	pLayerCfg.WindowX0 = 0;
	pLayerCfg.WindowX1 = 0;
	pLayerCfg.WindowY0 = 0;
	pLayerCfg.WindowY1 = 0;
	pLayerCfg.PixelFormat = LTDC_PIXEL_FORMAT_ARGB8888;
	pLayerCfg.Alpha = 0;
	pLayerCfg.Alpha0 = 0;
	pLayerCfg.BlendingFactor1 = LTDC_BLENDING_FACTOR1_CA;
	pLayerCfg.BlendingFactor2 = LTDC_BLENDING_FACTOR2_CA;
	pLayerCfg.FBStartAdress = 0;
	pLayerCfg.ImageWidth = 0;
	pLayerCfg.ImageHeight = 0;
	pLayerCfg.Backcolor.Blue = 0;
	pLayerCfg.Backcolor.Green = 0;
	pLayerCfg.Backcolor.Red = 0;
	if (HAL_LTDC_ConfigLayer(&hltdc, &pLayerCfg, 0) != HAL_OK) {
		Error_Handler();
	}
	pLayerCfg1.WindowX0 = 0;
	pLayerCfg1.WindowX1 = 0;
	pLayerCfg1.WindowY0 = 0;
	pLayerCfg1.WindowY1 = 0;
	pLayerCfg1.PixelFormat = LTDC_PIXEL_FORMAT_ARGB8888;
	pLayerCfg1.Alpha = 0;
	pLayerCfg1.Alpha0 = 0;
	pLayerCfg1.BlendingFactor1 = LTDC_BLENDING_FACTOR1_CA;
	pLayerCfg1.BlendingFactor2 = LTDC_BLENDING_FACTOR2_CA;
	pLayerCfg1.FBStartAdress = 0;
	pLayerCfg1.ImageWidth = 0;
	pLayerCfg1.ImageHeight = 0;
	pLayerCfg1.Backcolor.Blue = 0;
	pLayerCfg1.Backcolor.Green = 0;
	pLayerCfg1.Backcolor.Red = 0;
	if (HAL_LTDC_ConfigLayer(&hltdc, &pLayerCfg1, 1) != HAL_OK) {
		Error_Handler();
	}

}

static void MX_SDMMC2_SD_Init(void) {

	hsd2.Instance = SDMMC2;
	hsd2.Init.ClockEdge = SDMMC_CLOCK_EDGE_RISING;
	hsd2.Init.ClockBypass = SDMMC_CLOCK_BYPASS_DISABLE;
	hsd2.Init.ClockPowerSave = SDMMC_CLOCK_POWER_SAVE_DISABLE;
	hsd2.Init.BusWide = SDMMC_BUS_WIDE_1B;
	hsd2.Init.HardwareFlowControl = SDMMC_HARDWARE_FLOW_CONTROL_DISABLE;
	hsd2.Init.ClockDiv = 0;

}

static void MX_TIM6_Init(void) {

	TIM_MasterConfigTypeDef sMasterConfig = { 0 };

	htim6.Instance = TIM6;
	htim6.Init.Prescaler = 9999;
	htim6.Init.CounterMode = TIM_COUNTERMODE_UP;
	htim6.Init.Period = 9999;
	htim6.Init.AutoReloadPreload = TIM_AUTORELOAD_PRELOAD_DISABLE;
	if (HAL_TIM_Base_Init(&htim6) != HAL_OK) {
		Error_Handler();
	}
	sMasterConfig.MasterOutputTrigger = TIM_TRGO_RESET;
	sMasterConfig.MasterSlaveMode = TIM_MASTERSLAVEMODE_DISABLE;
	if (HAL_TIMEx_MasterConfigSynchronization(&htim6, &sMasterConfig)
			!= HAL_OK) {
		Error_Handler();
	}

}

static void MX_TIM7_Init(void) {

	TIM_MasterConfigTypeDef sMasterConfig = { 0 };

	htim7.Instance = TIM7;
	htim7.Init.Prescaler = 19999;
	htim7.Init.CounterMode = TIM_COUNTERMODE_UP;
	htim7.Init.Period = 9999;
	htim7.Init.AutoReloadPreload = TIM_AUTORELOAD_PRELOAD_DISABLE;
	if (HAL_TIM_Base_Init(&htim7) != HAL_OK) {
		Error_Handler();
	}
	sMasterConfig.MasterOutputTrigger = TIM_TRGO_RESET;
	sMasterConfig.MasterSlaveMode = TIM_MASTERSLAVEMODE_DISABLE;
	if (HAL_TIMEx_MasterConfigSynchronization(&htim7, &sMasterConfig)
			!= HAL_OK) {
		Error_Handler();
	}

}

/* FMC initialization function */
static void MX_FMC_Init(void) {

	FMC_SDRAM_TimingTypeDef SdramTiming = { 0 };

	/** Perform the SDRAM1 memory initialization sequence
	 */
	hsdram1.Instance = FMC_SDRAM_DEVICE;
	/* hsdram1.Init */
	hsdram1.Init.SDBank = FMC_SDRAM_BANK2;
	hsdram1.Init.ColumnBitsNumber = FMC_SDRAM_COLUMN_BITS_NUM_8;
	hsdram1.Init.RowBitsNumber = FMC_SDRAM_ROW_BITS_NUM_13;
	hsdram1.Init.MemoryDataWidth = FMC_SDRAM_MEM_BUS_WIDTH_32;
	hsdram1.Init.InternalBankNumber = FMC_SDRAM_INTERN_BANKS_NUM_4;
	hsdram1.Init.CASLatency = FMC_SDRAM_CAS_LATENCY_1;
	hsdram1.Init.WriteProtection = FMC_SDRAM_WRITE_PROTECTION_DISABLE;
	hsdram1.Init.SDClockPeriod = FMC_SDRAM_CLOCK_DISABLE;
	hsdram1.Init.ReadBurst = FMC_SDRAM_RBURST_DISABLE;
	hsdram1.Init.ReadPipeDelay = FMC_SDRAM_RPIPE_DELAY_0;
	/* SdramTiming */
	SdramTiming.LoadToActiveDelay = 16;
	SdramTiming.ExitSelfRefreshDelay = 16;
	SdramTiming.SelfRefreshTime = 16;
	SdramTiming.RowCycleDelay = 16;
	SdramTiming.WriteRecoveryTime = 16;
	SdramTiming.RPDelay = 16;
	SdramTiming.RCDDelay = 16;

	if (HAL_SDRAM_Init(&hsdram1, &SdramTiming) != HAL_OK) {
		Error_Handler();
	}

}

static void MX_GPIO_Init(void) {
	GPIO_InitTypeDef GPIO_InitStruct = { 0 };

	/* GPIO Ports Clock Enable */
	__HAL_RCC_GPIOE_CLK_ENABLE()
	;
	__HAL_RCC_GPIOB_CLK_ENABLE()
	;
	__HAL_RCC_GPIOD_CLK_ENABLE()
	;
	__HAL_RCC_GPIOG_CLK_ENABLE()
	;
	__HAL_RCC_GPIOI_CLK_ENABLE()
	;
	__HAL_RCC_GPIOF_CLK_ENABLE()
	;
	__HAL_RCC_GPIOH_CLK_ENABLE()
	;
	__HAL_RCC_GPIOA_CLK_ENABLE()
	;
	__HAL_RCC_GPIOJ_CLK_ENABLE()
	;

	/*Configure GPIO pin : PI13 */
	GPIO_InitStruct.Pin = GPIO_PIN_13;
	GPIO_InitStruct.Mode = GPIO_MODE_IT_RISING;
	GPIO_InitStruct.Pull = GPIO_NOPULL;
	HAL_GPIO_Init(GPIOI, &GPIO_InitStruct);

	/*Configure GPIO pin : PI15 */
	GPIO_InitStruct.Pin = GPIO_PIN_15;
	GPIO_InitStruct.Mode = GPIO_MODE_INPUT;
	GPIO_InitStruct.Pull = GPIO_NOPULL;
	HAL_GPIO_Init(GPIOI, &GPIO_InitStruct);

	/*Configure GPIO pin : PA0 */
	GPIO_InitStruct.Pin = GPIO_PIN_0;
	GPIO_InitStruct.Mode = GPIO_MODE_IT_RISING;
	GPIO_InitStruct.Pull = GPIO_NOPULL;
	HAL_GPIO_Init(GPIOA, &GPIO_InitStruct);

	/* EXTI interrupt init*/
	HAL_NVIC_SetPriority(EXTI0_IRQn, 0, 0);
	HAL_NVIC_EnableIRQ(EXTI0_IRQn);

	HAL_NVIC_SetPriority(EXTI15_10_IRQn, 0, 0);
	HAL_NVIC_EnableIRQ(EXTI15_10_IRQn);

}

/* USER CODE BEGIN 4 */
void HAL_GPIO_EXTI_Callback(uint16_t GPIO_Pin) {

//Vai buscar os valores de X e Y
	if (GPIO_Pin == GPIO_PIN_13 && touch_timer) {
		tsFlag = 1;
		touch_timer = 0;

		BSP_TS_GetState(&TS_State);
		touchXvalue = (int) TS_State.touchX[0];
		touchYvalue = (int) TS_State.touchY[0];

		if(touchYvalue <= 30 || touchYvalue >= 460){			//Goal EXTRA
			play_timer = 20;									//Goal EXTRA
			total_time = 0;										//Goal EXTRA
		}
	}
	if (GPIO_Pin == GPIO_PIN_0) {
		//blue_button = 1;
		num_plays++;				//Goal EXTRA
		BSP_LED_Off(LED_RED);		//Goal EXTRA
		BSP_LED_Off(LED_GREEN);		//Goal EXTRA
	}
}

void HAL_TIM_PeriodElapsedCallback(TIM_HandleTypeDef *htim) {

	//Está configurado para 1 segundo
	if (htim->Instance == TIM6) {
		play_timer--;
		total_time++;
		touch_timer = 1;
		timer_1s = 1;
	}

	if (htim->Instance == TIM7)
		timer7Flag = 1;

}

void HAL_ADC_ConvCpltCallback(ADC_HandleTypeDef* adcHandle) {

//ADC da temperatura
	if (adcHandle == &hadc1) {
		hadc1Value = HAL_ADC_GetValue(&hadc1);
	}
}

void LCD_Config_Start(void) {

	/* LCD DO MENU */
	uint32_t lcd_status = LCD_OK;

	/* Initialize the LCD */
	lcd_status = BSP_LCD_Init();
	while (lcd_status != LCD_OK)
		;

	BSP_LCD_LayerDefaultInit(0, LCD_FB_START_ADDRESS);

	/* Clear the LCD */
	BSP_LCD_Clear(LCD_COLOR_WHITE);

	/* Set LCD Example description */
	BSP_LCD_SetTextColor(LCD_COLOR_BLACK);
	BSP_LCD_FillRect(0, 0, BSP_LCD_GetXSize(), 120);
	BSP_LCD_SetTextColor(LCD_COLOR_WHITE);
	BSP_LCD_SetBackColor(LCD_COLOR_BLACK);
	BSP_LCD_SetFont(&Font24);
	BSP_LCD_DisplayStringAt(0, 50, (uint8_t *) "REVERSI GAME", CENTER_MODE);

	BSP_LCD_SetBackColor(LCD_COLOR_WHITE);
	BSP_LCD_SetTextColor(LCD_COLOR_BLACK);

	BSP_LCD_SetFont(&Font16);
	BSP_LCD_DisplayStringAt(35, 150, (uint8_t *) "SINGLEPLAYER", LEFT_MODE);
	BSP_LCD_DrawVLine(200, 0, 600);

	BSP_LCD_SetFont(&Font16);
	BSP_LCD_DisplayStringAt(240, 150, (uint8_t *) "MULTIPLAYER", LEFT_MODE);
	BSP_LCD_DrawVLine(400, 0, 600);

	BSP_LCD_SetFont(&Font16);
	BSP_LCD_DisplayStringAt(440, 150, (uint8_t *) "HIGH SCORES", LEFT_MODE);
	BSP_LCD_DrawVLine(600, 0, 600);

	BSP_LCD_SetFont(&Font16);
	BSP_LCD_DisplayStringAt(670, 150, (uint8_t *) "RULES", LEFT_MODE);

	BSP_LCD_SetTextColor(LCD_COLOR_BLACK);
	BSP_LCD_SetBackColor(LCD_COLOR_WHITE);
	BSP_LCD_SetFont(&Font24);
}

void LCD_Config_Rules(void) {

	char string[50];

	BSP_LCD_SetTextColor(LCD_COLOR_BLACK);
	BSP_LCD_FillRect(0, 0, BSP_LCD_GetXSize(), 120);
	BSP_LCD_SetTextColor(LCD_COLOR_WHITE);
	BSP_LCD_SetBackColor(LCD_COLOR_BLACK);
	BSP_LCD_SetFont(&Font24);
	BSP_LCD_DisplayStringAt(0, 50, (uint8_t *) "RULES", CENTER_MODE);

	BSP_LCD_SetFont(&Font16);
	BSP_LCD_SetBackColor(LCD_COLOR_WHITE);
	BSP_LCD_SetTextColor(LCD_COLOR_BLACK);
	BSP_LCD_DisplayStringAt(0, 180,
			(uint8_t *) "Four pieces have to be placed in the central squares of the board, so",
			CENTER_MODE);
	BSP_LCD_DisplayStringAt(0, 200,
			(uint8_t *) "that each pair of pieces of the same color form a diagonal between them.",
			CENTER_MODE);
	BSP_LCD_DisplayStringAt(0, 220,
			(uint8_t *) "The player with red pieces moves first, only 1 move is made every turn.",
			CENTER_MODE);
	BSP_LCD_DisplayStringAt(0, 260,
			(uint8_t *) "If you don't know how to play, click everywhere till something happens.",
			CENTER_MODE);

	BSP_LCD_DisplayStringAt(0, 375,
			(uint8_t *) "Touch anywhere in the screen to get back to the MENU.",
			CENTER_MODE);

	BSP_LCD_SetTextColor(LCD_COLOR_BLACK);
	BSP_LCD_FillRect(0, 460, BSP_LCD_GetXSize(), 30);
	BSP_LCD_SetTextColor(LCD_COLOR_WHITE);
	BSP_LCD_SetBackColor(LCD_COLOR_BLACK);
	BSP_LCD_SetFont(&Font16);
	sprintf(string, "REVERSI GAME - DESIGNED BY (c) ALFONSO BRANDAO");
	BSP_LCD_DisplayStringAt(0, 460, (uint8_t *) string, CENTER_MODE);

}

void LCD_Gameplay(void) {

	draw_board();

	/* LEFT SIDE - PLAYER 1*/

	BSP_LCD_SetTextColor(LCD_COLOR_BLACK);
	BSP_LCD_DrawHLine(20, 40, 160);
	BSP_LCD_DrawVLine(20, 40, 400);
	BSP_LCD_DrawHLine(20, 440, 160);
	BSP_LCD_DrawVLine(180, 40, 400);

	BSP_LCD_SetTextColor(LCD_COLOR_RED);
	BSP_LCD_SetBackColor(LCD_COLOR_WHITE);
	BSP_LCD_SetFont(&Font16);
	BSP_LCD_DisplayStringAt(30, 50, (uint8_t *) "PLAYER 1", LEFT_MODE);

	BSP_LCD_SetTextColor(LCD_COLOR_BLACK);
	BSP_LCD_SetBackColor(LCD_COLOR_WHITE);
	BSP_LCD_SetFont(&Font16);
	BSP_LCD_DisplayStringAt(30, 80, (uint8_t *) "SCORE: ", LEFT_MODE);

	/* RIGHT SIDE - PLAYER 2*/

	BSP_LCD_DrawHLine(620, 40, 160);
	BSP_LCD_DrawVLine(620, 40, 400);
	BSP_LCD_DrawHLine(620, 440, 160);
	BSP_LCD_DrawVLine(780, 40, 400);

	BSP_LCD_SetTextColor(LCD_COLOR_GREEN);
	BSP_LCD_SetBackColor(LCD_COLOR_WHITE);
	BSP_LCD_SetFont(&Font16);
	BSP_LCD_DisplayStringAt(630, 50, (uint8_t *) "PLAYER 2", LEFT_MODE);

	BSP_LCD_SetTextColor(LCD_COLOR_BLACK);
	BSP_LCD_SetBackColor(LCD_COLOR_WHITE);
	BSP_LCD_SetFont(&Font16);
	BSP_LCD_DisplayStringAt(630, 80, (uint8_t *) "SCORE: ", LEFT_MODE);

}

/* USER CODE END 4 */

void Error_Handler(void) {
}

/************************ (C) COPYRIGHT STMicroelectronics *****END OF FILE****/
